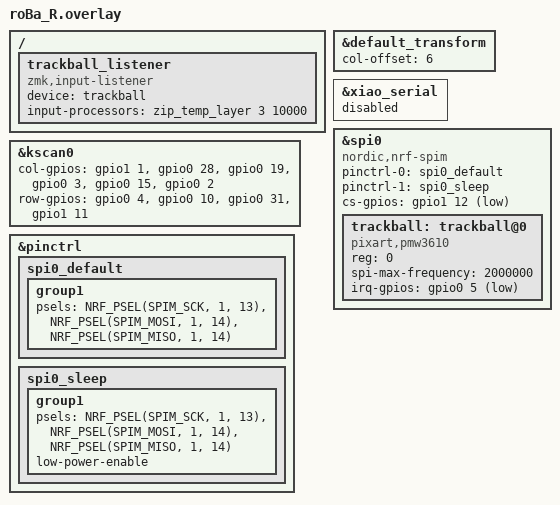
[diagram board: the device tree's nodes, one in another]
#include "roBa.dtsi"
#include <input/processors.dtsi>

&default_transform {
    col-offset = <6>;
};

&kscan0 {
        col-gpios
            = <&gpio1 1 GPIO_ACTIVE_HIGH>
            , <&gpio0 28 GPIO_ACTIVE_HIGH>
            , <&gpio0 19 GPIO_ACTIVE_HIGH>
            , <&gpio0 3 GPIO_ACTIVE_HIGH>
            , <&gpio0 15 GPIO_ACTIVE_HIGH>
            , <&gpio0 2 GPIO_ACTIVE_HIGH>
            ;
        row-gpios
            = <&gpio0 4 (GPIO_ACTIVE_HIGH | GPIO_PULL_DOWN)>
            , <&gpio0 10 (GPIO_ACTIVE_HIGH | GPIO_PULL_DOWN)>
            , <&gpio0 31 (GPIO_ACTIVE_HIGH | GPIO_PULL_DOWN)>
            , <&gpio1 11 (GPIO_ACTIVE_HIGH | GPIO_PULL_DOWN)>
            ;
};

/ {
    trackball_listener {
        status = "okay";
        compatible = "zmk,input-listener";
        device = <&trackball>;
        input-processors = <&zip_temp_layer 3 10000>;
    };
};

&pinctrl {
    spi0_default: spi0_default {
        group1 {
            psels = <NRF_PSEL(SPIM_SCK, 1, 13)>,
                <NRF_PSEL(SPIM_MOSI, 1, 14)>,
                <NRF_PSEL(SPIM_MISO, 1, 14)>;
        };
    };

    spi0_sleep: spi0_sleep {
        group1 {
            psels = <NRF_PSEL(SPIM_SCK, 1, 13)>,
                <NRF_PSEL(SPIM_MOSI, 1, 14)>,
                <NRF_PSEL(SPIM_MISO, 1, 14)>;
            low-power-enable;
        };
    };
};

&xiao_serial { status = "disabled"; };

&spi0 {
    status = "okay";
    compatible = "nordic,nrf-spim";
    pinctrl-0 = <&spi0_default>;
    pinctrl-1 = <&spi0_sleep>;
    pinctrl-names = "default", "sleep";
    cs-gpios = <&gpio1 12 GPIO_ACTIVE_LOW>;

    trackball: trackball@0 {
        status = "okay";
        compatible = "pixart,pmw3610";
        reg = <0>;
        spi-max-frequency = <2000000>;
        irq-gpios = <&gpio0 5 (GPIO_ACTIVE_LOW | GPIO_PULL_UP)>;
    };
};
